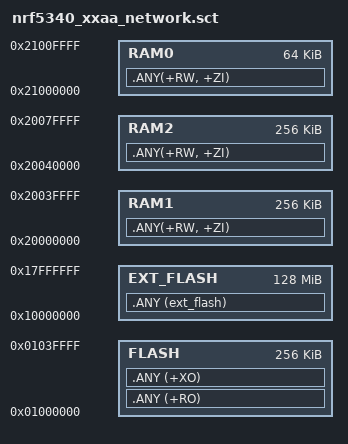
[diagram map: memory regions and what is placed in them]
LOAD 0x01000000 0x00040000
{
    FLASH 0x01000000 0x00040000
    {
    
        .ANY (+RO)
        .ANY (+XO)
    }
    EXT_FLASH 0x10000000 0x08000000
    {
    .ANY (ext_flash) ; Data or code allocated to external memory 
    }
    RAM0 0x21000000 0x00010000
    {
    .ANY(+RW, +ZI) ; RW data and ZI data
    }

    RAM1 0x20000000 0x00040000
    {
    .ANY(+RW, +ZI) ; RW data and ZI data
    }

    RAM2 0x20040000 0x00040000
    {
    .ANY(+RW, +ZI) ; RW data and ZI data
    }

}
